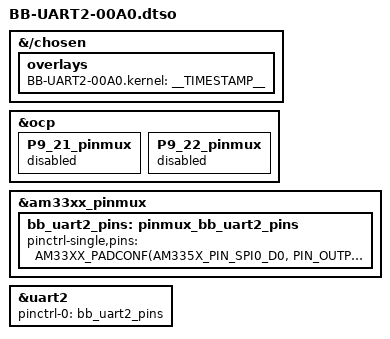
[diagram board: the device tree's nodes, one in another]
// SPDX-License-Identifier: GPL-2.0-only
/*
 * Copyright (C) 2013 CircuitCo
 * Virtual cape for UART2 on connector pins P9.21 P9.22
 */

/dts-v1/;
/plugin/;

#include <dt-bindings/pinctrl/am33xx.h>

/*
 * Helper to show loaded overlays under: /proc/device-tree/chosen/overlays/
 */
&{/chosen} {
	overlays {
		BB-UART2-00A0.kernel = __TIMESTAMP__;
	};
};

/*
 * Free up the pins used by the cape from the pinmux helpers.
 */
&ocp {
	P9_21_pinmux { status = "disabled"; };	/* P9_21: spi0_d0.uart2_txd */
	P9_22_pinmux { status = "disabled"; };	/* P9_22: spi0_sclk.uart2_rxd */
};

&am33xx_pinmux {
	bb_uart2_pins: pinmux_bb_uart2_pins {
		pinctrl-single,pins = <
			AM33XX_PADCONF(AM335X_PIN_SPI0_D0, PIN_OUTPUT, MUX_MODE1)	/* P9_21 spi0_d0.uart2_txd */
			AM33XX_PADCONF(AM335X_PIN_SPI0_SCLK, PIN_INPUT, MUX_MODE1)	/* P9_22 spi0_sclk.uart2_rxd */
			//AM33XX_PADCONF(AM335X_PIN_LCD_DATA9, PIN_OUTPUT, MUX_MODE6)	/* P8_38 lcd_data9.uart2_rtsn */
			//AM33XX_PADCONF(AM335X_PIN_LCD_DATA8, PIN_INPUT, MUX_MODE6)	/* P8_37 lcd_data8.uart2_ctsn */
		>;
	};
};

&uart2 {
	/* sudo agetty 115200 ttyS2 */
	status = "okay";
	pinctrl-names = "default";
	pinctrl-0 = <&bb_uart2_pins>;
};
